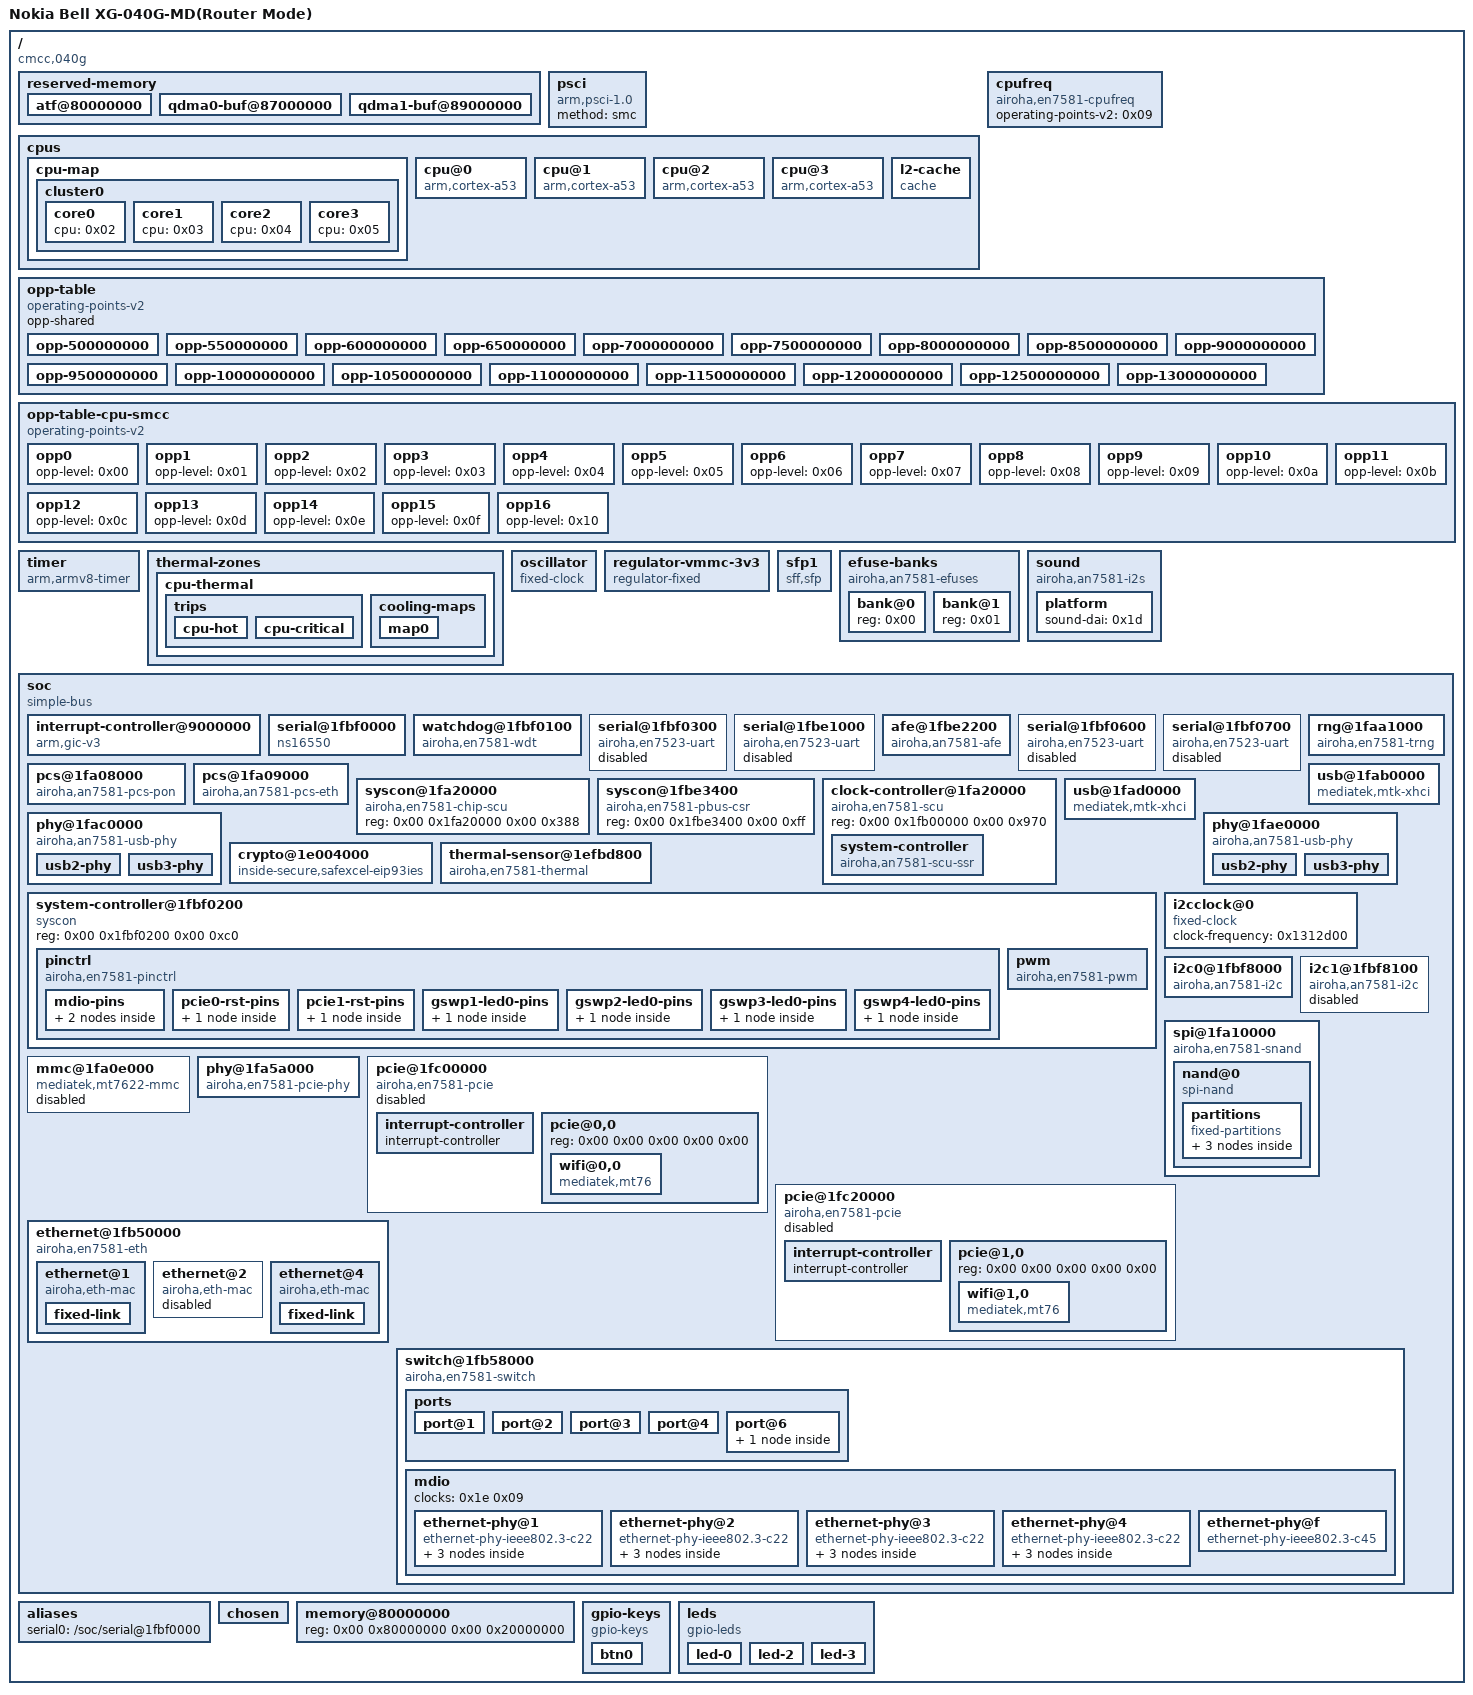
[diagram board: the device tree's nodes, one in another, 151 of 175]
/dts-v1/;

/ {
	interrupt-parent = <0x01>;
	#address-cells = <0x02>;
	#size-cells = <0x02>;
	model = "Nokia Bell XG-040G-MD(Router Mode)";
	compatible = "cmcc,040g", "airoha,an7581", "airoha,en7581";

	reserved-memory {
		#address-cells = <0x02>;
		#size-cells = <0x02>;
		ranges;

		atf@80000000 {
			no-map;
			reg = <0x00 0x80000000 0x00 0x200000>;
		};

		qdma0-buf@87000000 {
			no-map;
			reg = <0x00 0x87000000 0x00 0x2000000>;
			phandle = <0x34>;
		};

		qdma1-buf@89000000 {
			no-map;
			reg = <0x00 0x89000000 0x00 0x1000000>;
			phandle = <0x35>;
		};
	};

	psci {
		compatible = "arm,psci-1.0";
		method = "smc";
	};

	cpus {
		#address-cells = <0x01>;
		#size-cells = <0x00>;

		cpu-map {

			cluster0 {

				core0 {
					cpu = <0x02>;
				};

				core1 {
					cpu = <0x03>;
				};

				core2 {
					cpu = <0x04>;
				};

				core3 {
					cpu = <0x05>;
				};
			};
		};

		cpu@0 {
			device_type = "cpu";
			compatible = "arm,cortex-a53";
			reg = <0x00>;
			operating-points-v2 = <0x06>;
			enable-method = "psci";
			clocks = <0x07>;
			clock-names = "cpu";
			power-domains = <0x07>;
			power-domain-names = "perf";
			next-level-cache = <0x08>;
			#cooling-cells = <0x02>;
			phandle = <0x02>;
		};

		cpu@1 {
			device_type = "cpu";
			compatible = "arm,cortex-a53";
			reg = <0x01>;
			operating-points-v2 = <0x06>;
			enable-method = "psci";
			clocks = <0x07>;
			clock-names = "cpu";
			power-domains = <0x07>;
			power-domain-names = "perf";
			next-level-cache = <0x08>;
			#cooling-cells = <0x02>;
			phandle = <0x03>;
		};

		cpu@2 {
			device_type = "cpu";
			compatible = "arm,cortex-a53";
			reg = <0x02>;
			operating-points-v2 = <0x06>;
			enable-method = "psci";
			clocks = <0x07>;
			clock-names = "cpu";
			power-domains = <0x07>;
			power-domain-names = "perf";
			next-level-cache = <0x08>;
			#cooling-cells = <0x02>;
			phandle = <0x04>;
		};

		cpu@3 {
			device_type = "cpu";
			compatible = "arm,cortex-a53";
			reg = <0x03>;
			operating-points-v2 = <0x06>;
			enable-method = "psci";
			clocks = <0x07>;
			clock-names = "cpu";
			power-domains = <0x07>;
			power-domain-names = "perf";
			next-level-cache = <0x08>;
			#cooling-cells = <0x02>;
			phandle = <0x05>;
		};

		l2-cache {
			compatible = "cache";
			cache-size = <0x80000>;
			cache-line-size = <0x40>;
			cache-level = <0x02>;
			cache-unified;
			phandle = <0x08>;
		};
	};

	cpufreq {
		compatible = "airoha,en7581-cpufreq";
		operating-points-v2 = <0x09>;
		#power-domain-cells = <0x00>;
		#clock-cells = <0x00>;
		phandle = <0x07>;
	};

	opp-table {
		compatible = "operating-points-v2";
		opp-shared;
		phandle = <0x06>;

		opp-500000000 {
			opp-hz = <0x00 0x1dcd6500>;
			required-opps = <0x0a>;
		};

		opp-550000000 {
			opp-hz = <0x00 0x20c85580>;
			required-opps = <0x0b>;
		};

		opp-600000000 {
			opp-hz = <0x00 0x23c34600>;
			required-opps = <0x0c>;
		};

		opp-650000000 {
			opp-hz = <0x00 0x26be3680>;
			required-opps = <0x0d>;
		};

		opp-7000000000 {
			opp-hz = <0x00 0x29b92700>;
			required-opps = <0x0e>;
		};

		opp-7500000000 {
			opp-hz = <0x00 0x2cb41780>;
			required-opps = <0x0f>;
		};

		opp-8000000000 {
			opp-hz = <0x00 0x2faf0800>;
			required-opps = <0x10>;
		};

		opp-8500000000 {
			opp-hz = <0x00 0x32a9f880>;
			required-opps = <0x11>;
		};

		opp-9000000000 {
			opp-hz = <0x00 0x35a4e900>;
			required-opps = <0x12>;
		};

		opp-9500000000 {
			opp-hz = <0x00 0x389fd980>;
			required-opps = <0x13>;
		};

		opp-10000000000 {
			opp-hz = <0x00 0x3b9aca00>;
			required-opps = <0x14>;
		};

		opp-10500000000 {
			opp-hz = <0x00 0x3e95ba80>;
			required-opps = <0x15>;
		};

		opp-11000000000 {
			opp-hz = <0x00 0x4190ab00>;
			required-opps = <0x16>;
		};

		opp-11500000000 {
			opp-hz = <0x00 0x448b9b80>;
			required-opps = <0x17>;
		};

		opp-12000000000 {
			opp-hz = <0x00 0x47868c00>;
			required-opps = <0x18>;
		};

		opp-12500000000 {
			opp-hz = <0x00 0x4a817c80>;
			required-opps = <0x19>;
		};

		opp-13000000000 {
			opp-hz = <0x00 0x4d7c6d00>;
			required-opps = <0x1a>;
		};
	};

	opp-table-cpu-smcc {
		compatible = "operating-points-v2";
		phandle = <0x09>;

		opp0 {
			opp-level = <0x00>;
			phandle = <0x0a>;
		};

		opp1 {
			opp-level = <0x01>;
			phandle = <0x0b>;
		};

		opp2 {
			opp-level = <0x02>;
			phandle = <0x0c>;
		};

		opp3 {
			opp-level = <0x03>;
			phandle = <0x0d>;
		};

		opp4 {
			opp-level = <0x04>;
			phandle = <0x0e>;
		};

		opp5 {
			opp-level = <0x05>;
			phandle = <0x0f>;
		};

		opp6 {
			opp-level = <0x06>;
			phandle = <0x10>;
		};

		opp7 {
			opp-level = <0x07>;
			phandle = <0x11>;
		};

		opp8 {
			opp-level = <0x08>;
			phandle = <0x12>;
		};

		opp9 {
			opp-level = <0x09>;
			phandle = <0x13>;
		};

		opp10 {
			opp-level = <0x0a>;
			phandle = <0x14>;
		};

		opp11 {
			opp-level = <0x0b>;
			phandle = <0x15>;
		};

		opp12 {
			opp-level = <0x0c>;
			phandle = <0x16>;
		};

		opp13 {
			opp-level = <0x0d>;
			phandle = <0x17>;
		};

		opp14 {
			opp-level = <0x0e>;
			phandle = <0x18>;
		};

		opp15 {
			opp-level = <0x0f>;
			phandle = <0x19>;
		};

		opp16 {
			opp-level = <0x10>;
			phandle = <0x1a>;
		};
	};

	timer {
		compatible = "arm,armv8-timer";
		interrupt-parent = <0x01>;
		interrupts = <0x01 0x0d 0x08 0x01 0x0e 0x08 0x01 0x0b 0x08 0x01 0x0a 0x08>;
	};

	thermal-zones {

		cpu-thermal {
			polling-delay-passive = <0x00>;
			polling-delay = <0x00>;
			thermal-sensors = <0x1b 0x00>;

			trips {

				cpu-hot {
					temperature = <0x17318>;
					hysteresis = <0x3e8>;
					type = "hot";
					phandle = <0x1c>;
				};

				cpu-critical {
					temperature = <0x1adb0>;
					hysteresis = <0x3e8>;
					type = "critical";
				};
			};

			cooling-maps {

				map0 {
					trip = <0x1c>;
					cooling-device = <0x02 0xffffffff 0xffffffff 0x03 0xffffffff 0xffffffff 0x04 0xffffffff 0xffffffff 0x05 0xffffffff 0xffffffff>;
				};
			};
		};
	};

	oscillator {
		compatible = "fixed-clock";
		#clock-cells = <0x00>;
		clock-frequency = <0x17d7840>;
		clock-output-names = "clkxtal";
		phandle = <0x26>;
	};

	regulator-vmmc-3v3 {
		compatible = "regulator-fixed";
		regulator-name = "vmmc";
		regulator-min-microvolt = <0x325aa0>;
		regulator-max-microvolt = <0x325aa0>;
		regulator-always-on;
		phandle = <0x27>;
	};

	sfp1 {
		compatible = "sff,sfp";
	};

	efuse-banks {
		compatible = "airoha,an7581-efuses";
		#address-cells = <0x01>;
		#size-cells = <0x00>;

		bank@0 {
			reg = <0x00>;
		};

		bank@1 {
			reg = <0x01>;
		};
	};

	sound {
		compatible = "airoha,an7581-i2s";

		platform {
			sound-dai = <0x1d>;
		};
	};

	soc {
		compatible = "simple-bus";
		#address-cells = <0x02>;
		#size-cells = <0x02>;
		ranges;

		interrupt-controller@9000000 {
			compatible = "arm,gic-v3";
			interrupt-controller;
			#interrupt-cells = <0x03>;
			#address-cells = <0x01>;
			#size-cells = <0x01>;
			reg = <0x00 0x9000000 0x00 0x20000 0x00 0x9080000 0x00 0x80000 0x00 0x9400000 0x00 0x2000 0x00 0x9500000 0x00 0x2000 0x00 0x9600000 0x00 0x20000>;
			interrupts = <0x01 0x09 0x08>;
			phandle = <0x01>;
		};

		serial@1fbf0000 {
			compatible = "ns16550";
			reg = <0x00 0x1fbf0000 0x00 0x30>;
			reg-io-width = <0x04>;
			reg-shift = <0x02>;
			interrupts = <0x00 0x12 0x04>;
			clock-frequency = <0x1c2000>;
		};

		watchdog@1fbf0100 {
			compatible = "airoha,en7581-wdt";
			reg = <0x00 0x1fbf0100 0x00 0x38>;
			clocks = <0x1e 0x02>;
			clock-names = "bus";
		};

		serial@1fbf0300 {
			compatible = "airoha,en7523-uart";
			reg = <0x00 0x1fbf0300 0x00 0x30>;
			reg-io-width = <0x04>;
			reg-shift = <0x02>;
			interrupts = <0x00 0x20 0x04>;
			clock-frequency = <0x708000>;
			status = "disabled";
		};

		serial@1fbe1000 {
			compatible = "airoha,en7523-uart";
			reg = <0x00 0x1fbe1000 0x00 0x40>;
			reg-io-width = <0x04>;
			reg-shift = <0x02>;
			interrupts = <0x00 0x36 0x04>;
			clock-frequency = <0x708000>;
			status = "disabled";
		};

		afe@1fbe2200 {
			compatible = "airoha,an7581-afe";
			reg = <0x1fbe2200 0x9000>;
			interrupts = <0x00 0x30 0x04>;
			phandle = <0x1d>;
		};

		serial@1fbf0600 {
			compatible = "airoha,en7523-uart";
			reg = <0x00 0x1fbf0600 0x00 0x30>;
			reg-io-width = <0x04>;
			reg-shift = <0x02>;
			interrupts = <0x00 0x3d 0x04>;
			clock-frequency = <0x708000>;
			status = "disabled";
		};

		serial@1fbf0700 {
			compatible = "airoha,en7523-uart";
			reg = <0x00 0x1fbf0700 0x00 0x30>;
			reg-io-width = <0x04>;
			reg-shift = <0x02>;
			interrupts = <0x00 0x12 0x04>;
			clock-frequency = <0x708000>;
			status = "disabled";
		};

		pcs@1fa08000 {
			compatible = "airoha,an7581-pcs-pon";
			reg = <0x00 0x1fa08000 0x00 0x1000 0x00 0x1fa80000 0x00 0x60 0x00 0x1fa80a00 0x00 0x164 0x00 0x1fa84000 0x00 0x450 0x00 0x1fa85900 0x00 0x338 0x00 0x1fa86000 0x00 0x300 0x00 0x1fa8a000 0x00 0x1000 0x00 0x1fa8b000 0x00 0x1000>;
			reg-names = "xfi_mac", "hsgmii_an", "hsgmii_pcs", "multi_sgmii", "usxgmii", "hsgmii_rate_adp", "xfi_ana", "xfi_pma";
			resets = <0x1e 0x34 0x1e 0x00>;
			reset-names = "mac", "phy";
			airoha,scu = <0x1e>;
			phandle = <0x36>;
		};

		pcs@1fa09000 {
			compatible = "airoha,an7581-pcs-eth";
			reg = <0x00 0x1fa09000 0x00 0x1000 0x00 0x1fa70000 0x00 0x60 0x00 0x1fa70a00 0x00 0x164 0x00 0x1fa74000 0x00 0x450 0x00 0x1fa75900 0x00 0x338 0x00 0x1fa76000 0x00 0x300 0x00 0x1fa7a000 0x00 0x1000 0x00 0x1fa7b000 0x00 0x1000>;
			reg-names = "xfi_mac", "hsgmii_an", "hsgmii_pcs", "multi_sgmii", "usxgmii", "hsgmii_rate_adp", "xfi_ana", "xfi_pma";
			resets = <0x1e 0x06 0x1e 0x07>;
			reset-names = "mac", "phy";
			airoha,scu = <0x1e>;
			phandle = <0x37>;
		};

		syscon@1fa20000 {
			compatible = "airoha,en7581-chip-scu", "syscon";
			reg = <0x00 0x1fa20000 0x00 0x388>;
			phandle = <0x23>;
		};

		syscon@1fbe3400 {
			compatible = "airoha,en7581-pbus-csr", "syscon";
			reg = <0x00 0x1fbe3400 0x00 0xff>;
			phandle = <0x29>;
		};

		clock-controller@1fa20000 {
			compatible = "airoha,en7581-scu", "syscon";
			reg = <0x00 0x1fb00000 0x00 0x970>;
			#clock-cells = <0x01>;
			#reset-cells = <0x01>;
			phandle = <0x1e>;

			system-controller {
				compatible = "airoha,an7581-scu-ssr";
				phandle = <0x22>;
			};
		};

		rng@1faa1000 {
			compatible = "airoha,en7581-trng";
			reg = <0x00 0x1faa1000 0x00 0xc04>;
			interrupts = <0x00 0x23 0x04>;
		};

		usb@1fab0000 {
			compatible = "mediatek,mtk-xhci";
			reg = <0x00 0x1fab0000 0x00 0x3e00 0x00 0x1fab3e00 0x00 0x100>;
			reg-names = "mac", "ippc";
			interrupts = <0x00 0x21 0x04>;
			phys = <0x1f 0x03 0x20 0x04>;
			status = "okay";
		};

		usb@1fad0000 {
			compatible = "mediatek,mtk-xhci";
			reg = <0x00 0x1fad0000 0x00 0x3e00 0x00 0x1fad3e00 0x00 0x100>;
			reg-names = "mac", "ippc";
			interrupts = <0x00 0x96 0x04>;
			phys = <0x21 0x03>;
			status = "okay";
			mediatek,u3p-dis-msk = <0x01>;
		};

		phy@1fac0000 {
			compatible = "airoha,an7581-usb-phy";
			reg = <0x00 0x1fac0000 0x00 0x10000>;
			airoha,port-id = <0x00>;
			airoha,scu-ssr = <0x22>;
			airoha,scu = <0x1e>;
			airoha,usb2-monitor-clk-sel = <0x01>;
			airoha,serdes-port = <0x02>;

			usb2-phy {
				#phy-cells = <0x01>;
				phandle = <0x1f>;
			};

			usb3-phy {
				#phy-cells = <0x01>;
				phandle = <0x20>;
			};
		};

		phy@1fae0000 {
			compatible = "airoha,an7581-usb-phy";
			reg = <0x00 0x1fae0000 0x00 0x10000>;
			airoha,port-id = <0x01>;
			airoha,scu-ssr = <0x22>;
			airoha,scu = <0x1e>;
			airoha,usb2-monitor-clk-sel = <0x02>;
			airoha,serdes-port = <0x03>;

			usb2-phy {
				#phy-cells = <0x01>;
				phandle = <0x21>;
			};

			usb3-phy {
				#phy-cells = <0x01>;
			};
		};

		crypto@1e004000 {
			compatible = "inside-secure,safexcel-eip93ies";
			reg = <0x00 0x1fb70000 0x00 0x1000>;
			interrupts = <0x00 0x2c 0x04>;
		};

		thermal-sensor@1efbd800 {
			compatible = "airoha,en7581-thermal";
			reg = <0x00 0x1efbd000 0x00 0xd5c>;
			interrupts = <0x00 0x17 0x04>;
			airoha,chip-scu = <0x23>;
			#thermal-sensor-cells = <0x00>;
			phandle = <0x1b>;
		};

		system-controller@1fbf0200 {
			compatible = "syscon", "simple-mfd";
			reg = <0x00 0x1fbf0200 0x00 0xc0>;

			pinctrl {
				compatible = "airoha,en7581-pinctrl";
				interrupt-parent = <0x01>;
				interrupts = <0x00 0x1a 0x04>;
				gpio-controller;
				#gpio-cells = <0x02>;
				interrupt-controller;
				#interrupt-cells = <0x02>;
				gpio-ranges = <0x24 0x00 0x0d 0x2f>;
				phandle = <0x24>;

				mdio-pins {
					phandle = <0x39>;

					mux {
						function = "mdio";
						groups = "mdio";
					};

					conf {
						pins = "gpio2";
						output-enable;
					};
				};

				pcie0-rst-pins {
					phandle = <0x2b>;

					conf {
						pins = "pcie_reset0";
						drive-open-drain = <0x01>;
					};
				};

				pcie1-rst-pins {
					phandle = <0x2f>;

					conf {
						pins = "pcie_reset1";
						drive-open-drain = <0x01>;
					};
				};

				gswp1-led0-pins {
					phandle = <0x3f>;

					mux {
						function = "phy1_led0";
						groups = "gpio33";
					};
				};

				gswp2-led0-pins {
					phandle = <0x40>;

					mux {
						function = "phy2_led0";
						groups = "gpio34";
					};
				};

				gswp3-led0-pins {
					phandle = <0x41>;

					mux {
						function = "phy3_led0";
						groups = "gpio35";
					};
				};

				gswp4-led0-pins {
					phandle = <0x42>;

					mux {
						function = "phy4_led0";
						groups = "gpio42";
					};
				};
			};

			pwm {
				compatible = "airoha,en7581-pwm";
				#pwm-cells = <0x03>;
			};
		};

		i2cclock@0 {
			#clock-cells = <0x00>;
			compatible = "fixed-clock";
			clock-frequency = <0x1312d00>;
			phandle = <0x25>;
		};

		i2c0@1fbf8000 {
			compatible = "airoha,an7581-i2c";
			reg = <0x00 0x1fbf8000 0x00 0x100>;
			clocks = <0x25>;
			clock-frequency = <0x186a0>;
			#address-cells = <0x01>;
			#size-cells = <0x00>;
			status = "okay";
		};

		i2c1@1fbf8100 {
			compatible = "airoha,an7581-i2c";
			reg = <0x00 0x1fbf8100 0x00 0x100>;
			clocks = <0x25>;
			clock-frequency = <0x186a0>;
			#address-cells = <0x01>;
			#size-cells = <0x00>;
			status = "disable";
		};

		spi@1fa10000 {
			compatible = "airoha,en7581-snand";
			reg = <0x00 0x1fa10000 0x00 0x140 0x00 0x1fa11000 0x00 0x160>;
			clocks = <0x1e 0x04>;
			clock-names = "spi";
			#address-cells = <0x01>;
			#size-cells = <0x00>;
			status = "okay";

			nand@0 {
				compatible = "spi-nand";
				reg = <0x00>;
				spi-max-frequency = <0x2faf080>;
				spi-tx-bus-width = <0x01>;
				spi-rx-bus-width = <0x02>;

				partitions {
					compatible = "fixed-partitions";
					#address-cells = <0x01>;
					#size-cells = <0x01>;

					partition@0 {
						label = "bootloader";
						reg = <0x00 0x80000>;
					};

					partition@80000 {
						label = "env";
						reg = <0x80000 0x80000>;
					};

					partition@100000 {
						label = "ubi";
						reg = <0x100000 0x00>;
					};
				};
			};
		};

		mmc@1fa0e000 {
			compatible = "mediatek,mt7622-mmc";
			reg = <0x00 0x1fa0e000 0x00 0x1000 0x00 0x1fa0c000 0x00 0x60>;
			interrupts = <0x00 0xaa 0x04>;
			clocks = <0x1e 0x08 0x26>;
			clock-names = "source", "hclk";
			bus-width = <0x04>;
			max-frequency = <0x3197500>;
			vmmc-supply = <0x27>;
			disable-wp;
			cap-mmc-highspeed;
			non-removable;
			status = "disabled";
		};

		phy@1fa5a000 {
			compatible = "airoha,en7581-pcie-phy";
			reg = <0x00 0x1fa5a000 0x00 0xfff 0x00 0x1fa5b000 0x00 0xfff 0x00 0x1fa5c000 0x00 0xfff 0x00 0x1fc10044 0x00 0x04 0x00 0x1fc30044 0x00 0x04 0x00 0x1fc15030 0x00 0x104>;
			reg-names = "csr-2l", "pma0", "pma1", "p0-xr-dtime", "p1-xr-dtime", "rx-aeq";
			#phy-cells = <0x00>;
			phandle = <0x28>;
		};

		pcie@1fc00000 {
			compatible = "airoha,en7581-pcie";
			device_type = "pci";
			linux,pci-domain = <0x00>;
			#address-cells = <0x03>;
			#size-cells = <0x02>;
			reg = <0x00 0x1fc00000 0x00 0x1670>;
			reg-names = "pcie-mac";
			clocks = <0x1e 0x07>;
			clock-names = "sys-ck";
			phys = <0x28>;
			phy-names = "pcie-phy";
			ranges = <0x2000000 0x00 0x20000000 0x00 0x20000000 0x00 0x4000000>;
			resets = <0x1e 0x30 0x1e 0x31 0x1e 0x19>;
			reset-names = "phy-lane0", "phy-lane1", "phy-lane2";
			mediatek,pbus-csr = <0x29 0x00 0x04>;
			interrupts = <0x00 0x27 0x04>;
			bus-range = <0x00 0xff>;
			#interrupt-cells = <0x01>;
			interrupt-map-mask = <0x00 0x00 0x00 0x07>;
			interrupt-map = <0x00 0x00 0x00 0x01 0x2a 0x00 0x00 0x00 0x00 0x02 0x2a 0x01 0x00 0x00 0x00 0x03 0x2a 0x02 0x00 0x00 0x00 0x04 0x2a 0x03>;
			status = "disabled";
			pinctrl-names = "default";
			pinctrl-0 = <0x2b>;

			interrupt-controller {
				interrupt-controller;
				#address-cells = <0x00>;
				#interrupt-cells = <0x01>;
				phandle = <0x2a>;
			};

			pcie@0,0 {
				reg = <0x00 0x00 0x00 0x00 0x00>;

				wifi@0,0 {
					compatible = "mediatek,mt76";
					reg = <0x00 0x00 0x00 0x00 0x00>;
					airoha,eth = <0x2d>;
				};
			};
		};

		pcie@1fc20000 {
			compatible = "airoha,en7581-pcie";
			device_type = "pci";
			linux,pci-domain = <0x01>;
			#address-cells = <0x03>;
			#size-cells = <0x02>;
			reg = <0x00 0x1fc20000 0x00 0x1670>;
			reg-names = "pcie-mac";
			clocks = <0x1e 0x07>;
			clock-names = "sys-ck";
			phys = <0x28>;
			phy-names = "pcie-phy";
			ranges = <0x2000000 0x00 0x24000000 0x00 0x24000000 0x00 0x4000000>;
			resets = <0x1e 0x30 0x1e 0x31 0x1e 0x19>;
			reset-names = "phy-lane0", "phy-lane1", "phy-lane2";
			mediatek,pbus-csr = <0x29 0x08 0x0c>;
			interrupts = <0x00 0x28 0x04>;
			bus-range = <0x00 0xff>;
			#interrupt-cells = <0x01>;
			interrupt-map-mask = <0x00 0x00 0x00 0x07>;
			interrupt-map = <0x00 0x00 0x00 0x01 0x2e 0x00 0x00 0x00 0x00 0x02 0x2e 0x01 0x00 0x00 0x00 0x03 0x2e 0x02 0x00 0x00 0x00 0x04 0x2e 0x03>;
			status = "disabled";
			pinctrl-names = "default";
			pinctrl-0 = <0x2f>;

			interrupt-controller {
				interrupt-controller;
				#address-cells = <0x00>;
				#interrupt-cells = <0x01>;
				phandle = <0x2e>;
			};

			pcie@1,0 {
				reg = <0x00 0x00 0x00 0x00 0x00>;

				wifi@1,0 {
					compatible = "mediatek,mt76";
					reg = <0x00 0x00 0x00 0x00 0x00>;
					airoha,eth = <0x2d>;
				};
			};
		};

		ethernet@1fb50000 {
			compatible = "airoha,en7581-eth";
			reg = <0x00 0x1fb50000 0x00 0x2600 0x00 0x1fb54000 0x00 0x2000 0x00 0x1fb56000 0x00 0x2000>;
			reg-names = "fe", "qdma0", "qdma1";
			resets = <0x1e 0x2c 0x1e 0x1e 0x1e 0x1f 0x1e 0x0f 0x1e 0x10 0x1e 0x11 0x1e 0x1a>;
			reset-names = "fe", "pdma", "qdma", "hsi0-mac", "hsi1-mac", "hsi-mac", "xfp-mac";
			interrupts = <0x00 0x25 0x04 0x00 0x37 0x04 0x00 0x38 0x04 0x00 0x39 0x04 0x00 0x26 0x04 0x00 0x3a 0x04 0x00 0x3b 0x04 0x00 0x3c 0x04 0x00 0x31 0x04 0x00 0x40 0x04>;
			memory-region = <0x34 0x35>;
			memory-region-names = "qdma0-buf", "qdma1-buf";
			status = "okay";
			#address-cells = <0x01>;
			#size-cells = <0x00>;
			phandle = <0x2d>;

			ethernet@1 {
				compatible = "airoha,eth-mac";
				reg = <0x01>;
				phy-mode = "internal";
				status = "okay";
				phandle = <0x3e>;

				fixed-link {
					speed = <0x2710>;
					full-duplex;
					pause;
				};
			};

			ethernet@2 {
				compatible = "airoha,eth-mac";
				reg = <0x02>;
				pcs = <0x36>;
				status = "disabled";
			};

			ethernet@4 {
				compatible = "airoha,eth-mac";
				reg = <0x04>;
				pcs = <0x37>;
				status = "okay";
				phy-handle = <0x38>;
				phy-mode = "2500base-x";

				fixed-link {
					speed = <0x9c4>;
					full-duplex;
				};
			};
		};

		switch@1fb58000 {
			compatible = "airoha,en7581-switch";
			reg = <0x00 0x1fb58000 0x00 0x8000>;
			resets = <0x1e 0x2e>;
			interrupt-controller;
			#interrupt-cells = <0x01>;
			interrupt-parent = <0x01>;
			interrupts = <0x00 0xd1 0x04>;
			status = "okay";
			#address-cells = <0x01>;
			#size-cells = <0x01>;
			pinctrl-names = "default";
			pinctrl-0 = <0x39>;

			ports {
				#address-cells = <0x01>;
				#size-cells = <0x00>;

				port@1 {
					reg = <0x01>;
					label = "lan1";
					phy-mode = "internal";
					phy-handle = <0x3a>;
				};

				port@2 {
					reg = <0x02>;
					label = "lan2";
					phy-mode = "internal";
					phy-handle = <0x3b>;
				};

				port@3 {
					reg = <0x03>;
					label = "lan3";
					phy-mode = "internal";
					phy-handle = <0x3c>;
				};

				port@4 {
					reg = <0x04>;
					label = "lan4";
					phy-mode = "internal";
					phy-handle = <0x3d>;
				};

				port@6 {
					reg = <0x06>;
					label = "cpu";
					ethernet = <0x3e>;
					phy-mode = "internal";

					fixed-link {
						speed = <0x2710>;
						full-duplex;
						pause;
					};
				};
			};

			mdio {
				#address-cells = <0x01>;
				#size-cells = <0x00>;
				clocks = <0x1e 0x09>;

				ethernet-phy@1 {
					compatible = "ethernet-phy-ieee802.3-c22";
					reg = <0x09>;
					phy-mode = "internal";
					pinctrl-names = "gbe-led";
					pinctrl-0 = <0x3f>;
					status = "okay";
					phandle = <0x3a>;

					leds {
						#address-cells = <0x01>;
						#size-cells = <0x00>;

						gsw-phy1-led0@0 {
							reg = <0x00>;
							function = "phy1_led0";
							status = "okay";
							active-low;
						};

						gsw-phy1-led1@1 {
							reg = <0x01>;
							function = "phy1_led1";
							status = "disabled";
						};
					};
				};

				ethernet-phy@2 {
					compatible = "ethernet-phy-ieee802.3-c22";
					reg = <0x0a>;
					phy-mode = "internal";
					pinctrl-names = "gbe-led";
					pinctrl-0 = <0x40>;
					status = "okay";
					phandle = <0x3b>;

					leds {
						#address-cells = <0x01>;
						#size-cells = <0x00>;

						gsw-phy2-led0@0 {
							reg = <0x00>;
							function = "phy2_led0";
							status = "okay";
							active-low;
						};

						gsw-phy2-led1@1 {
							reg = <0x01>;
							function = "phy1_led1";
							status = "disabled";
						};
					};
				};

				ethernet-phy@3 {
					compatible = "ethernet-phy-ieee802.3-c22";
					reg = <0x0b>;
					phy-mode = "internal";
					pinctrl-names = "gbe-led";
					pinctrl-0 = <0x41>;
					status = "okay";
					phandle = <0x3c>;

					leds {
						#address-cells = <0x01>;
						#size-cells = <0x00>;

						gsw-phy3-led0@0 {
							reg = <0x00>;
							function = "lan";
							status = "okay";
							active-low;
						};

						gsw-phy3-led1@1 {
							reg = <0x01>;
							function = "lan";
							status = "disabled";
						};
					};
				};

				ethernet-phy@4 {
					compatible = "ethernet-phy-ieee802.3-c22";
					reg = <0x0c>;
					phy-mode = "internal";
					pinctrl-names = "gbe-led";
					pinctrl-0 = <0x42>;
					status = "okay";
					phandle = <0x3d>;

					leds {
						#address-cells = <0x01>;
						#size-cells = <0x00>;

						gsw-phy4-led0@0 {
							reg = <0x00>;
							function = "lan";
							status = "okay";
							active-low;
						};

						gsw-phy4-led1@1 {
							reg = <0x01>;
							function = "lan";
							status = "disabled";
						};
					};
				};

				ethernet-phy@f {
					compatible = "ethernet-phy-ieee802.3-c45";
					reg = <0x0f>;
					phy-mode = "2500base-x";
					phandle = <0x38>;
				};
			};
		};
	};

	aliases {
		serial0 = "/soc/serial@1fbf0000";
	};

	chosen {
		bootargs = "console=ttyS0,115200 earlycon";
		stdout-path = "serial0:115200n8";
		linux,usable-memory-range = <0x00 0x80200000 0x00 0x7fe00000>;
	};

	memory@80000000 {
		device_type = "memory";
		reg = <0x00 0x80000000 0x00 0x20000000>;
	};

	gpio-keys {
		compatible = "gpio-keys";

		btn0 {
			label = "reset";
			linux,code = <0x198>;
			gpios = <0x24 0x00 0x01>;
		};
	};

	leds {
		compatible = "gpio-leds";

		led-0 {
			label = "pwr";
			color = <0x01>;
			function = "power";
			gpios = <0x24 0x11 0x01>;
			default-state = "on";
		};

		led-2 {
			label = "pon";
			color = <0x02>;
			function = "status";
			gpios = <0x24 0x13 0x01>;
			default-state = "off";
		};

		led-3 {
			label = "internet";
			color = <0x02>;
			function = "status";
			gpios = <0x24 0x14 0x01>;
			default-state = "on";
		};
	};
};
